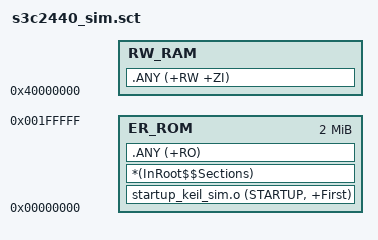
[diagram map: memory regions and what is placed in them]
; =============================================================
; Scatter File for Mini2440 Simulator (Run at 0x00000000)
; =============================================================

LR_ROM 0x00000000 0x00200000
{
    ER_ROM 0x00000000 0x00200000
    {
        startup_keil_sim.o (STARTUP, +First)
        *(InRoot$$Sections)
        .ANY (+RO)
    }

    RW_RAM 0x40000000
    {
        .ANY (+RW +ZI)
    }
}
